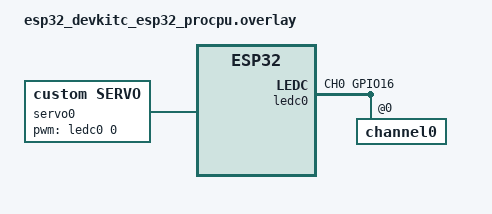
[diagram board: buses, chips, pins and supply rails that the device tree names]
#include <zephyr/dt-bindings/pwm/pwm.h>

/ {
	servo0: servo_0 {
		compatible = "custom,servo";
		pwms = <&ledc0 0 PWM_MSEC(20) PWM_POLARITY_NORMAL>;
	};
};

&pinctrl {
	ledc0_default: ledc0_default {
		group1 {
			pinmux = <LEDC_CH0_GPIO16>;
			output-enable;
		};
	};
};

&ledc0 {
	pinctrl-0 = <&ledc0_default>;
	pinctrl-names = "default";
	status = "okay";
	#address-cells = <1>;
	#size-cells = <0>;

	channel0@0 {
		reg = <0x0>;
		timer = <0>;
	};
};
